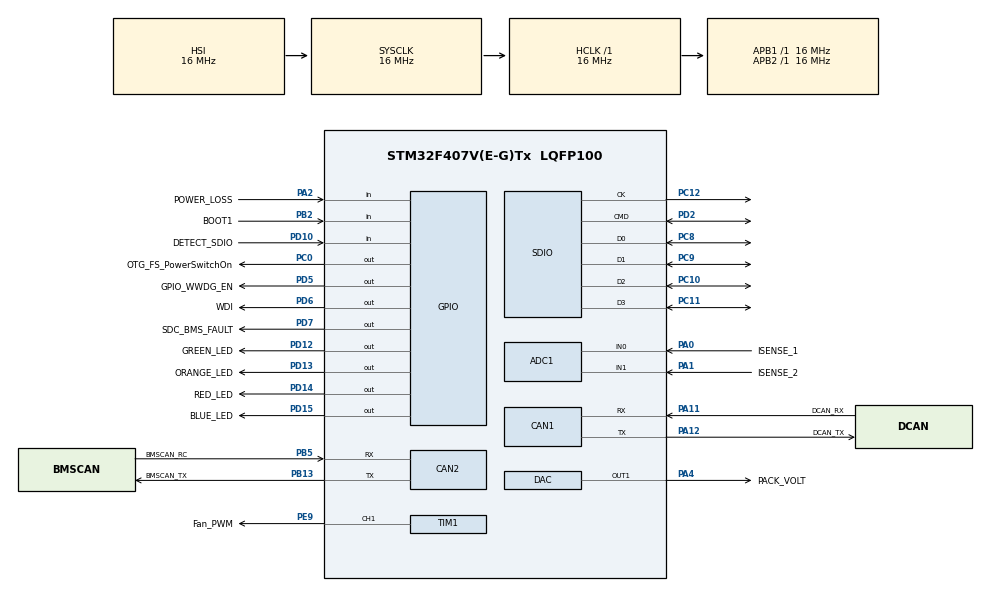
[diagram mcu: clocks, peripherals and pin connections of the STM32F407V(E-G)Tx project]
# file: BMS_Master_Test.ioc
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ADC1.Channel-0\#ChannelRegularConversion=ADC_CHANNEL_0
ADC1.NbrOfConversionFlag=1
ADC1.Rank-0\#ChannelRegularConversion=1
ADC1.SamplingTime-0\#ChannelRegularConversion=ADC_SAMPLETIME_3CYCLES
ADC1.master=1
CAN1.CalculateTimeQuantum=1000.0
CAN2.CalculateTimeQuantum=1000.0
FATFS.BSP.number=1
FATFS0.BSP.STBoard=false
FATFS0.BSP.api=Unknown
FATFS0.BSP.i2caddr=0
FATFS0.BSP.instance=PD10
FATFS0.BSP.ip=GPIO
FATFS0.BSP.mode=Input
FATFS0.BSP.name=Detect_SDIO
FATFS0.BSP.solution=PD10
FREERTOS.Tasks01=defaultTask,0,128,StartDefaultTask,Default,NULL
Mcu.Family=STM32F4
Mcu.Name=STM32F407V(E-G)Tx
Mcu.Package=LQFP100
NVIC.PriorityGroup=NVIC_PRIORITYGROUP_4
NVIC.TIM2_IRQn=true\:0\:0\:false\:false\:true\:false\:false\:true
NVIC.TimeBase=TIM2_IRQn
NVIC.TimeBaseIP=TIM2
PA0-WKUP.GPIO_Label=ISENSE_1
PA0-WKUP.Signal=ADCx_IN0
PA1.GPIO_Label=ISENSE_2
PA1.Signal=ADCx_IN1
PA11.GPIO_Label=DCAN_RX
PA11.Mode=Master
PA11.Signal=CAN1_RX
PA12.GPIO_Label=DCAN_TX
PA12.Mode=Master
PA12.Signal=CAN1_TX
PA13.GPIO_Label=SWDIO
PA13.Mode=JTAG_4_pins
PA13.Signal=SYS_JTMS-SWDIO
PA14.GPIO_Label=SWCLK
PA14.Mode=JTAG_4_pins
PA14.Signal=SYS_JTCK-SWCLK
PA15.Mode=JTAG_4_pins
PA15.Signal=SYS_JTDI
PA2.GPIO_Label=POWER_LOSS
PA2.Signal=GPIO_Input
PA4.GPIO_Label=PACK_VOLT
PA4.Signal=COMP_DAC1_group
PB13.GPIO_Label=BMSCAN_TX
PB13.Mode=Slave
PB13.Signal=CAN2_TX
PB2.GPIO_Label=BOOT1
PB2.GPIO_Mode=GPIO_MODE_INPUT
PB2.GPIO_PuPd=GPIO_NOPULL
PB2.Signal=GPIO_Input
PB3.GPIO_Label=SWO
PB3.Mode=JTAG_4_pins
PB3.Signal=SYS_JTDO-SWO
PB5.GPIO_Label=BMSCAN_RC
PB5.Mode=Slave
PB5.Signal=CAN2_RX
PC0.GPIO_Label=OTG_FS_PowerSwitchOn
PC0.GPIO_PuPd=GPIO_NOPULL
PC0.GPIO_Speed=GPIO_SPEED_FREQ_LOW
PC0.PinState=GPIO_PIN_SET
PC0.Signal=GPIO_Output
PC10.Mode=SD_4_bits_Wide_bus
PC10.Signal=SDIO_D2
PC11.Mode=SD_4_bits_Wide_bus
PC11.Signal=SDIO_D3
PC12.Mode=SD_4_bits_Wide_bus
PC12.Signal=SDIO_CK
PC8.Mode=SD_4_bits_Wide_bus
PC8.Signal=SDIO_D0
PC9.Mode=SD_4_bits_Wide_bus
PC9.Signal=SDIO_D1
PD10.GPIO_Label=DETECT_SDIO
PD10.Signal=GPIO_Input
PD12.GPIO_Label=GREEN_LED
PD12.GPIO_PuPd=GPIO_NOPULL
PD12.GPIO_Speed=GPIO_SPEED_FREQ_LOW
PD12.Signal=GPIO_Output
PD13.GPIO_Label=ORANGE_LED
PD13.GPIO_PuPd=GPIO_NOPULL
PD13.GPIO_Speed=GPIO_SPEED_FREQ_LOW
PD13.Signal=GPIO_Output
PD14.GPIO_Label=RED_LED
PD14.GPIO_PuPd=GPIO_NOPULL
PD14.GPIO_Speed=GPIO_SPEED_FREQ_LOW
PD14.Signal=GPIO_Output
PD15.GPIO_Label=BLUE_LED
PD15.GPIO_PuPd=GPIO_NOPULL
PD15.GPIO_Speed=GPIO_SPEED_FREQ_LOW
PD15.Signal=GPIO_Output
PD2.Mode=SD_4_bits_Wide_bus
PD2.Signal=SDIO_CMD
PD5.GPIO_Label=GPIO_WWDG_EN
PD5.Signal=GPIO_Output
PD6.GPIO_Label=WDI
PD6.Signal=GPIO_Output
PD7.GPIO_Label=SDC_BMS_FAULT
PD7.Signal=GPIO_Output
PE9.GPIO_Label=Fan_PWM
PE9.Signal=S_TIM1_CH1
PH0-OSC_IN.GPIO_Label=PH0-OSC_IN
PH0-OSC_IN.Mode=HSE-External-Oscillator
PH0-OSC_IN.Signal=RCC_OSC_IN
PH1-OSC_OUT.GPIO_Label=PH1-OSC_OUT
PH1-OSC_OUT.Mode=HSE-External-Oscillator
PH1-OSC_OUT.Signal=RCC_OSC_OUT
ProjectManager.HeapSize=0x200
ProjectManager.StackSize=0x400
ProjectManager.TargetToolchain=SW4STM32
RCC.48MHZClocksFreq_Value=14285714.285714285
RCC.AHBFreq_Value=16000000
RCC.APB1Freq_Value=16000000
RCC.APB1TimFreq_Value=16000000
RCC.APB2Freq_Value=16000000
RCC.APB2TimFreq_Value=16000000
RCC.CortexFreq_Value=16000000
RCC.HCLKFreq_Value=16000000
RCC.HSE_VALUE=8000000
RCC.HSI_VALUE=16000000
RCC.LSE_VALUE=32768
RCC.PLLM=8
RCC.PLLN=50
RCC.PLLP=RCC_PLLP_DIV4
RCC.PLLQ=7
RCC.SYSCLKFreq_VALUE=16000000
RCC.VCOOutputFreq_Value=100000000
SH.ADCx_IN0.0=ADC1_IN0,IN0
SH.ADCx_IN1.0=ADC1_IN1,IN1
SH.COMP_DAC1_group.0=DAC_OUT1,DAC_OUT1
SH.S_TIM1_CH1.0=TIM1_CH1,PWM Generation1 CH1
TIM1.Channel-PWM\ Generation1\ CH1=TIM_CHANNEL_1
VP_FATFS_VS_SDIO.Mode=SDIO
VP_FREERTOS_VS_CMSIS_V1.Mode=CMSIS_V1
VP_SYS_VS_tim2.Mode=TIM2
board=STM32F407G-DISC1

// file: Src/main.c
/* USER CODE BEGIN Header */
/**
  ******************************************************************************
  * @file           : main.c
  * @brief          : Main program body
  ******************************************************************************
  * @attention
  *
  * <h2><center>&copy; Copyright (c) 2019 STMicroelectronics.
  * All rights reserved.</center></h2>
  *
  * This software component is licensed by ST under Ultimate Liberty license
  * SLA0044, the "License"; You may not use this file except in compliance with
  * the License. You may obtain a copy of the License at:
  *                             www.st.com/SLA0044
  *
  ******************************************************************************
  */
/* USER CODE END Header */

#include "main.h"
#include "cmsis_os.h"
#include "fatfs.h"

ADC_HandleTypeDef hadc1;

CAN_HandleTypeDef hcan1;
CAN_HandleTypeDef hcan2;

DAC_HandleTypeDef hdac;

SD_HandleTypeDef hsd1;

TIM_HandleTypeDef htim1;

osThreadId defaultTaskHandle;

void SystemClock_Config(void);
static void MX_GPIO_Init(void);
static void MX_ADC1_Init(void);
static void MX_TIM1_Init(void);
static void MX_CAN1_Init(void);
static void MX_CAN2_Init(void);
static void MX_SDIO_SD_Init(void);
static void MX_DAC_Init(void);
void StartDefaultTask(void const * argument);

int main(void)
{

  /* MCU Configuration--------------------------------------------------------*/

  /* Reset of all peripherals, Initializes the Flash interface and the Systick. */
  HAL_Init();

  /* Configure the system clock */
  SystemClock_Config();

  /* Initialize all configured peripherals */
  MX_GPIO_Init();
  MX_ADC1_Init();
  MX_TIM1_Init();
  MX_CAN1_Init();
  MX_CAN2_Init();
  MX_SDIO_SD_Init();
  MX_DAC_Init();

  /* USER CODE BEGIN 2 */
  bms_can_filter_init(&hcan2);
  HAL_CAN_Start(&hcan2);
  dcan_filter_init(&hcan1);
  HAL_CAN_Start(&hcan1);

  HAL_CAN_ActivateNotification(&hcan1, CAN_IT_RX_FIFO0_MSG_PENDING);

  //BMS_can is a stand alone master so has access to both fifo's
  HAL_CAN_ActivateNotification(&hcan2, CAN_IT_RX_FIFO0_MSG_PENDING);
  HAL_CAN_ActivateNotification(&hcan2, CAN_IT_RX_FIFO1_MSG_PENDING);

  initRTOSObjects();
  /* USER CODE END 2 */

  /* Create the thread(s) */
  /* definition and creation of defaultTask */
  osThreadDef(defaultTask, StartDefaultTask, osPriorityNormal, 0, 128);
  defaultTaskHandle = osThreadCreate(osThread(defaultTask), NULL);

  /* Start scheduler */
  osKernelStart();

  /* We should never get here as control is now taken by the scheduler */

  /* Infinite loop */
  while (1)
  {

  }
}

void SystemClock_Config(void)
{
  RCC_OscInitTypeDef RCC_OscInitStruct = {0};
  RCC_ClkInitTypeDef RCC_ClkInitStruct = {0};

  /** Configure the main internal regulator output voltage
  */
  __HAL_RCC_PWR_CLK_ENABLE();
  __HAL_PWR_VOLTAGESCALING_CONFIG(PWR_REGULATOR_VOLTAGE_SCALE1);
  /** Initializes the CPU, AHB and APB busses clocks
  */
  RCC_OscInitStruct.OscillatorType = RCC_OSCILLATORTYPE_HSI;
  RCC_OscInitStruct.HSIState = RCC_HSI_ON;
  RCC_OscInitStruct.HSICalibrationValue = RCC_HSICALIBRATION_DEFAULT;
  RCC_OscInitStruct.PLL.PLLState = RCC_PLL_ON;
  RCC_OscInitStruct.PLL.PLLSource = RCC_PLLSOURCE_HSI;
  RCC_OscInitStruct.PLL.PLLM = 8;
  RCC_OscInitStruct.PLL.PLLN = 50;
  RCC_OscInitStruct.PLL.PLLP = RCC_PLLP_DIV4;
  RCC_OscInitStruct.PLL.PLLQ = 7;
  if (HAL_RCC_OscConfig(&RCC_OscInitStruct) != HAL_OK)
  {
    Error_Handler();
  }
  /** Initializes the CPU, AHB and APB busses clocks
  */
  RCC_ClkInitStruct.ClockType = RCC_CLOCKTYPE_HCLK|RCC_CLOCKTYPE_SYSCLK
                              |RCC_CLOCKTYPE_PCLK1|RCC_CLOCKTYPE_PCLK2;
  RCC_ClkInitStruct.SYSCLKSource = RCC_SYSCLKSOURCE_HSI;
  RCC_ClkInitStruct.AHBCLKDivider = RCC_SYSCLK_DIV1;
  RCC_ClkInitStruct.APB1CLKDivider = RCC_HCLK_DIV1;
  RCC_ClkInitStruct.APB2CLKDivider = RCC_HCLK_DIV1;

  if (HAL_RCC_ClockConfig(&RCC_ClkInitStruct, FLASH_LATENCY_0) != HAL_OK)
  {
    Error_Handler();
  }
}

static void MX_ADC1_Init(void)
{

  ADC_ChannelConfTypeDef sConfig = {0};

  /** Configure the global features of the ADC (Clock, Resolution, Data Alignment and number of conversion)
  */
  hadc1.Instance = ADC1;
  hadc1.Init.ClockPrescaler = ADC_CLOCK_SYNC_PCLK_DIV2;
  hadc1.Init.Resolution = ADC_RESOLUTION_12B;
  hadc1.Init.ScanConvMode = DISABLE;
  hadc1.Init.ContinuousConvMode = DISABLE;
  hadc1.Init.DiscontinuousConvMode = DISABLE;
  hadc1.Init.ExternalTrigConvEdge = ADC_EXTERNALTRIGCONVEDGE_NONE;
  hadc1.Init.ExternalTrigConv = ADC_SOFTWARE_START;
  hadc1.Init.DataAlign = ADC_DATAALIGN_RIGHT;
  hadc1.Init.NbrOfConversion = 1;
  hadc1.Init.DMAContinuousRequests = DISABLE;
  hadc1.Init.EOCSelection = ADC_EOC_SINGLE_CONV;
  if (HAL_ADC_Init(&hadc1) != HAL_OK)
  {
    Error_Handler();
  }
  /** Configure for the selected ADC regular channel its corresponding rank in the sequencer and its sample time.
  */
  sConfig.Channel = ADC_CHANNEL_0;
  sConfig.Rank = 1;
  sConfig.SamplingTime = ADC_SAMPLETIME_3CYCLES;
  if (HAL_ADC_ConfigChannel(&hadc1, &sConfig) != HAL_OK)
  {
    Error_Handler();
  }

}

static void MX_CAN1_Init(void)
{

  hcan1.Instance = CAN1;
  hcan1.Init.Prescaler = 16;
  hcan1.Init.Mode = CAN_MODE_NORMAL;
  hcan1.Init.SyncJumpWidth = CAN_SJW_1TQ;
  hcan1.Init.TimeSeg1 = CAN_BS1_1TQ;
  hcan1.Init.TimeSeg2 = CAN_BS2_1TQ;
  hcan1.Init.TimeTriggeredMode = DISABLE;
  hcan1.Init.AutoBusOff = DISABLE;
  hcan1.Init.AutoWakeUp = DISABLE;
  hcan1.Init.AutoRetransmission = DISABLE;
  hcan1.Init.ReceiveFifoLocked = DISABLE;
  hcan1.Init.TransmitFifoPriority = DISABLE;
  if (HAL_CAN_Init(&hcan1) != HAL_OK)
  {
    Error_Handler();
  }

}

static void MX_CAN2_Init(void)
{

  hcan2.Instance = CAN2;
  hcan2.Init.Prescaler = 16;
  hcan2.Init.Mode = CAN_MODE_NORMAL;
  hcan2.Init.SyncJumpWidth = CAN_SJW_1TQ;
  hcan2.Init.TimeSeg1 = CAN_BS1_1TQ;
  hcan2.Init.TimeSeg2 = CAN_BS2_1TQ;
  hcan2.Init.TimeTriggeredMode = DISABLE;
  hcan2.Init.AutoBusOff = DISABLE;
  hcan2.Init.AutoWakeUp = DISABLE;
  hcan2.Init.AutoRetransmission = DISABLE;
  hcan2.Init.ReceiveFifoLocked = DISABLE;
  hcan2.Init.TransmitFifoPriority = DISABLE;
  if (HAL_CAN_Init(&hcan2) != HAL_OK)
  {
    Error_Handler();
  }

}

static void MX_DAC_Init(void)
{

  DAC_ChannelConfTypeDef sConfig = {0};

  /** DAC Initialization
  */
  hdac.Instance = DAC;
  if (HAL_DAC_Init(&hdac) != HAL_OK)
  {
    Error_Handler();
  }
  /** DAC channel OUT1 config
  */
  sConfig.DAC_Trigger = DAC_TRIGGER_NONE;
  sConfig.DAC_OutputBuffer = DAC_OUTPUTBUFFER_ENABLE;
  if (HAL_DAC_ConfigChannel(&hdac, &sConfig, DAC_CHANNEL_1) != HAL_OK)
  {
    Error_Handler();
  }

}

static void MX_SDIO_SD_Init(void)
{

  hsd1.Instance = SDIO;
  hsd1.Init.ClockEdge = SDIO_CLOCK_EDGE_RISING;
  hsd1.Init.ClockBypass = SDIO_CLOCK_BYPASS_DISABLE;
  hsd1.Init.ClockPowerSave = SDIO_CLOCK_POWER_SAVE_DISABLE;
  hsd1.Init.BusWide = SDIO_BUS_WIDE_1B;
  hsd1.Init.HardwareFlowControl = SDIO_HARDWARE_FLOW_CONTROL_DISABLE;
  hsd1.Init.ClockDiv = 0;

}

static void MX_TIM1_Init(void)
{

  TIM_MasterConfigTypeDef sMasterConfig = {0};
  TIM_OC_InitTypeDef sConfigOC = {0};
  TIM_BreakDeadTimeConfigTypeDef sBreakDeadTimeConfig = {0};

  htim1.Instance = TIM1;
  htim1.Init.Prescaler = 0;
  htim1.Init.CounterMode = TIM_COUNTERMODE_UP;
  htim1.Init.Period = 0;
  htim1.Init.ClockDivision = TIM_CLOCKDIVISION_DIV1;
  htim1.Init.RepetitionCounter = 0;
  htim1.Init.AutoReloadPreload = TIM_AUTORELOAD_PRELOAD_DISABLE;
  if (HAL_TIM_PWM_Init(&htim1) != HAL_OK)
  {
    Error_Handler();
  }
  sMasterConfig.MasterOutputTrigger = TIM_TRGO_RESET;
  sMasterConfig.MasterSlaveMode = TIM_MASTERSLAVEMODE_DISABLE;
  if (HAL_TIMEx_MasterConfigSynchronization(&htim1, &sMasterConfig) != HAL_OK)
  {
    Error_Handler();
  }
  sConfigOC.OCMode = TIM_OCMODE_PWM1;
  sConfigOC.Pulse = 0;
  sConfigOC.OCPolarity = TIM_OCPOLARITY_HIGH;
  sConfigOC.OCNPolarity = TIM_OCNPOLARITY_HIGH;
  sConfigOC.OCFastMode = TIM_OCFAST_DISABLE;
  sConfigOC.OCIdleState = TIM_OCIDLESTATE_RESET;
  sConfigOC.OCNIdleState = TIM_OCNIDLESTATE_RESET;
  if (HAL_TIM_PWM_ConfigChannel(&htim1, &sConfigOC, TIM_CHANNEL_1) != HAL_OK)
  {
    Error_Handler();
  }
  sBreakDeadTimeConfig.OffStateRunMode = TIM_OSSR_DISABLE;
  sBreakDeadTimeConfig.OffStateIDLEMode = TIM_OSSI_DISABLE;
  sBreakDeadTimeConfig.LockLevel = TIM_LOCKLEVEL_OFF;
  sBreakDeadTimeConfig.DeadTime = 0;
  sBreakDeadTimeConfig.BreakState = TIM_BREAK_DISABLE;
  sBreakDeadTimeConfig.BreakPolarity = TIM_BREAKPOLARITY_HIGH;
  sBreakDeadTimeConfig.AutomaticOutput = TIM_AUTOMATICOUTPUT_DISABLE;
  if (HAL_TIMEx_ConfigBreakDeadTime(&htim1, &sBreakDeadTimeConfig) != HAL_OK)
  {
    Error_Handler();
  }
  HAL_TIM_MspPostInit(&htim1);

}

static void MX_GPIO_Init(void)
{
  GPIO_InitTypeDef GPIO_InitStruct = {0};

  /* GPIO Ports Clock Enable */
  __HAL_RCC_GPIOH_CLK_ENABLE();
  __HAL_RCC_GPIOC_CLK_ENABLE();
  __HAL_RCC_GPIOA_CLK_ENABLE();
  __HAL_RCC_GPIOB_CLK_ENABLE();
  __HAL_RCC_GPIOE_CLK_ENABLE();
  __HAL_RCC_GPIOD_CLK_ENABLE();

  /*Configure GPIO pin Output Level */
  HAL_GPIO_WritePin(OTG_FS_PowerSwitchOn_GPIO_Port, OTG_FS_PowerSwitchOn_Pin, GPIO_PIN_SET);

  /*Configure GPIO pin Output Level */
  HAL_GPIO_WritePin(GPIOD, GREEN_LED_Pin|ORANGE_LED_Pin|RED_LED_Pin|BLUE_LED_Pin
                          |GPIO_WWDG_EN_Pin|WDI_Pin|SDC_BMS_FAULT_Pin, GPIO_PIN_RESET);

  /*Configure GPIO pin : OTG_FS_PowerSwitchOn_Pin */
  GPIO_InitStruct.Pin = OTG_FS_PowerSwitchOn_Pin;
  GPIO_InitStruct.Mode = GPIO_MODE_OUTPUT_PP;
  GPIO_InitStruct.Pull = GPIO_NOPULL;
  GPIO_InitStruct.Speed = GPIO_SPEED_FREQ_LOW;
  HAL_GPIO_Init(OTG_FS_PowerSwitchOn_GPIO_Port, &GPIO_InitStruct);

  /*Configure GPIO pin : POWER_LOSS_Pin */
  GPIO_InitStruct.Pin = POWER_LOSS_Pin;
  GPIO_InitStruct.Mode = GPIO_MODE_INPUT;
  GPIO_InitStruct.Pull = GPIO_NOPULL;
  HAL_GPIO_Init(POWER_LOSS_GPIO_Port, &GPIO_InitStruct);

  /*Configure GPIO pin : BOOT1_Pin */
  GPIO_InitStruct.Pin = BOOT1_Pin;
  GPIO_InitStruct.Mode = GPIO_MODE_INPUT;
  GPIO_InitStruct.Pull = GPIO_NOPULL;
  HAL_GPIO_Init(BOOT1_GPIO_Port, &GPIO_InitStruct);

  /*Configure GPIO pin : DETECT_SDIO_Pin */
  GPIO_InitStruct.Pin = DETECT_SDIO_Pin;
  GPIO_InitStruct.Mode = GPIO_MODE_INPUT;
  GPIO_InitStruct.Pull = GPIO_NOPULL;
  HAL_GPIO_Init(DETECT_SDIO_GPIO_Port, &GPIO_InitStruct);

  /*Configure GPIO pins : GREEN_LED_Pin ORANGE_LED_Pin RED_LED_Pin BLUE_LED_Pin
                           GPIO_WWDG_EN_Pin WDI_Pin SDC_BMS_FAULT_Pin */
  GPIO_InitStruct.Pin = GREEN_LED_Pin|ORANGE_LED_Pin|RED_LED_Pin|BLUE_LED_Pin
                          |GPIO_WWDG_EN_Pin|WDI_Pin|SDC_BMS_FAULT_Pin;
  GPIO_InitStruct.Mode = GPIO_MODE_OUTPUT_PP;
  GPIO_InitStruct.Pull = GPIO_NOPULL;
  GPIO_InitStruct.Speed = GPIO_SPEED_FREQ_LOW;
  HAL_GPIO_Init(GPIOD, &GPIO_InitStruct);

}

void StartDefaultTask(void const * argument)
{

  /* init code for FATFS */
  MX_FATFS_Init();

  for(;;)
  {
    osDelay(1);
  }
}

void HAL_TIM_PeriodElapsedCallback(TIM_HandleTypeDef *htim)
{
  if (htim->Instance == TIM2) {
    HAL_IncTick();
  }
}

void Error_Handler(void)
{
}

/************************ (C) COPYRIGHT STMicroelectronics *****END OF FILE****/
